VERSION "WUFR 25.1.0"

BS_: 1000000 : 0,0

BU_: FSB DAQ RSB CTRLB

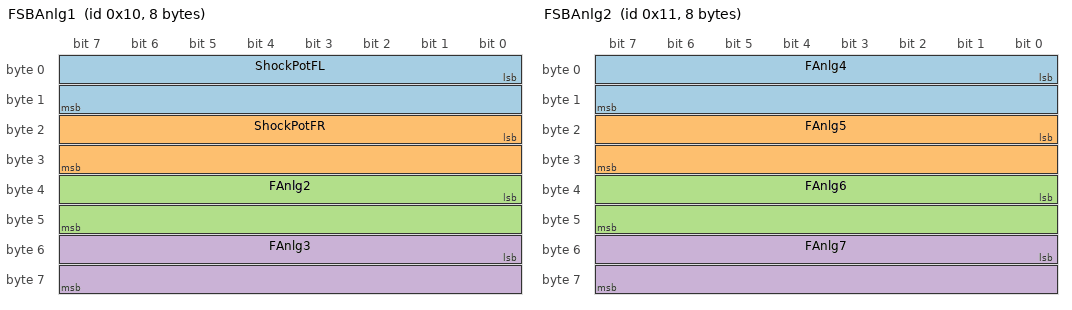
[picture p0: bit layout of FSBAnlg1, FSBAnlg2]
BO_ 16 FSBAnlg1: 8 FSB
 SG_ ShockPotFL : 0|16@1+ (0.013986,-0.0112) [0|50] "mm" DAQ
 SG_ ShockPotFR : 16|16@1+ (0.013986,-0.0112) [0|50] "mm" DAQ
 SG_ FAnlg2 : 32|16@1+ (0.001,0) [0|5] "V" DAQ
 SG_ FAnlg3 : 48|16@1+ (0.001,0) [0|5] "V" DAQ

BO_ 17 FSBAnlg2: 8 FSB
 SG_ FAnlg4 : 0|16@1+ (0.001,0) [0|5] "V" DAQ
 SG_ FAnlg5 : 16|16@1+ (0.001,0) [0|5] "V" DAQ
 SG_ FAnlg6 : 32|16@1+ (0.001,0) [0|5] "V" DAQ
 SG_ FAnlg7 : 48|16@1+ (0.001,0) [0|5] "V" DAQ

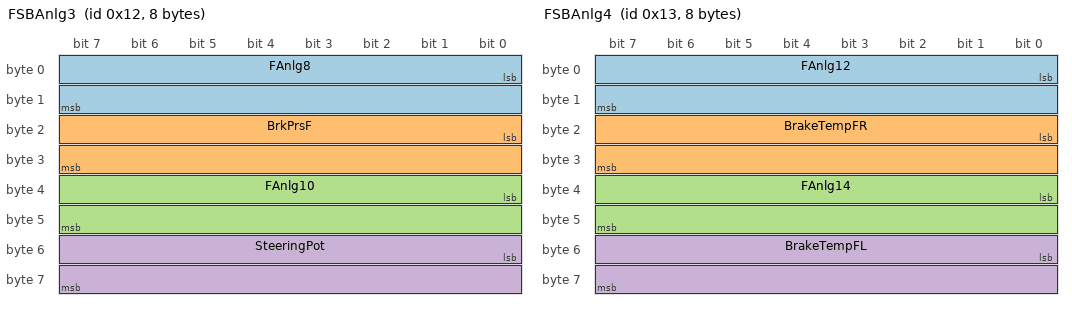
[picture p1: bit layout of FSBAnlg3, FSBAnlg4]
BO_ 18 FSBAnlg3: 8 FSB
 SG_ FAnlg8 : 0|16@1+ (0.001,0) [0|5] "V" DAQ
 SG_ BrkPrsF : 16|16@1+ (0.25,-125.0) [-125|1125] "Psi" DAQ
 SG_ FAnlg10 : 32|16@1+ (0.001,0) [0|5] "V" DAQ
 SG_ SteeringPot : 48|16@1+ (0.83044,-315.013) [-90|90] "deg" DAQ

BO_ 19 FSBAnlg4: 8 FSB
 SG_ FAnlg12 : 0|16@1+ (0.001,0) [0|5] "V" DAQ
 SG_ BrakeTempFR : 16|16@1+ (1.656,-968) [-148|1652] "F" DAQ
 SG_ FAnlg14 : 32|16@1+ (0.001,0) [0|5] "V" DAQ
 SG_ BrakeTempFL : 48|16@1+ (1.656,-968) [-148|1652] "F" DAQ

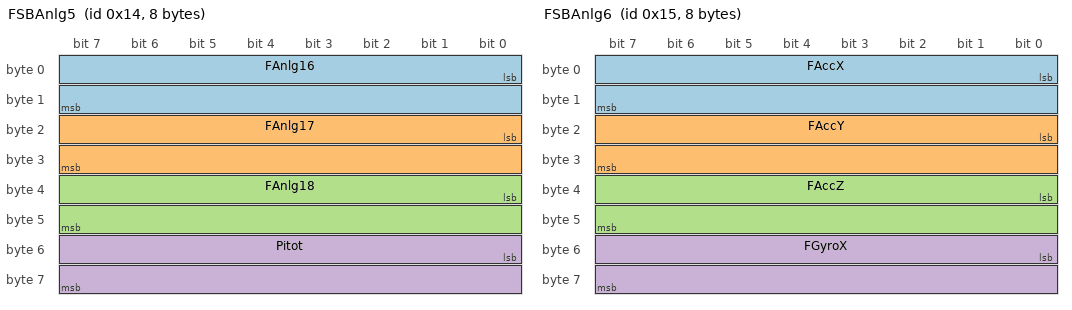
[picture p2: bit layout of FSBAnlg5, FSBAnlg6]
BO_ 20 FSBAnlg5: 8 FSB
 SG_ FAnlg16 : 0|16@1+ (0.001,0) [0|5] "V" DAQ
 SG_ FAnlg17 : 16|16@1+ (0.001,0) [0|5] "V" DAQ
 SG_ FAnlg18 : 32|16@1+ (0.001,0) [0|5] "V" DAQ
 SG_ Pitot : 48|16@1+ (0.00326,-1.63) [0|13.04] "mbar" DAQ

BO_ 21 FSBAnlg6: 8 FSB
 SG_ FAccX : 0|16@1- (0.01,0) [-3276|3276] "m/s^2" DAQ
 SG_ FAccY : 16|16@1- (0.01,0) [-3276|3276] "m/s^2" DAQ
 SG_ FAccZ : 32|16@1- (0.01,0) [-3276|3276] "m/s^2" DAQ
 SG_ FGyroX : 48|16@1- (0.01,0) [-3276|3276] "deg/s^2" DAQ

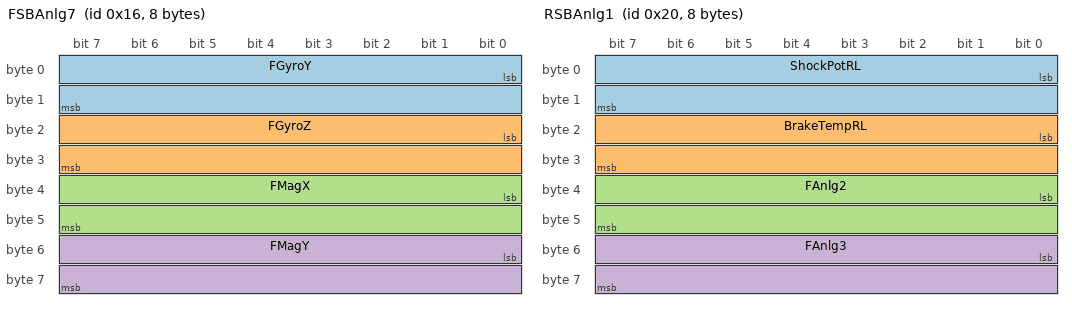
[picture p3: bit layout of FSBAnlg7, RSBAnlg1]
BO_ 22 FSBAnlg7: 8 FSB
 SG_ FGyroY : 0|16@1- (0.01,0) [-3276|3276] "deg/s^2" DAQ
 SG_ FGyroZ : 16|16@1- (0.01,0) [-3276|3276] "deg/s^2" DAQ
 SG_ FMagX : 32|16@1- (0.01,0) [-3276|3276] "#" DAQ
 SG_ FMagY : 48|16@1- (0.01,0) [-3276|3276] "#" DAQ

BO_ 23 FSBAnlg8: 8 FSB
 SG_ FMagZ : 0|16@1+ (0.01,0) [-3276|3276] "#" DAQ
 SG_ RideHeightFR : 16|16@1+ (1,0) [0,255] "mm" DAQ
 SG_ RideHeightFL : 32|16@1+ (1,0) [0,255] "mm" DAQ

BO_ 32 RSBAnlg1: 8 RSB
 SG_ ShockPotRL : 0|16@1+ (0.013986,-0.0112) [0|50] "mm" DAQ
 SG_ BrakeTempRL : 16|16@1+ (1.656,-968) [-148|1652] "F" DAQ
 SG_ FAnlg2 : 32|16@1+ (0.001,0) [0|5] "V" DAQ
 SG_ FAnlg3 : 48|16@1+ (0.001,0) [0|5] "V" DAQ

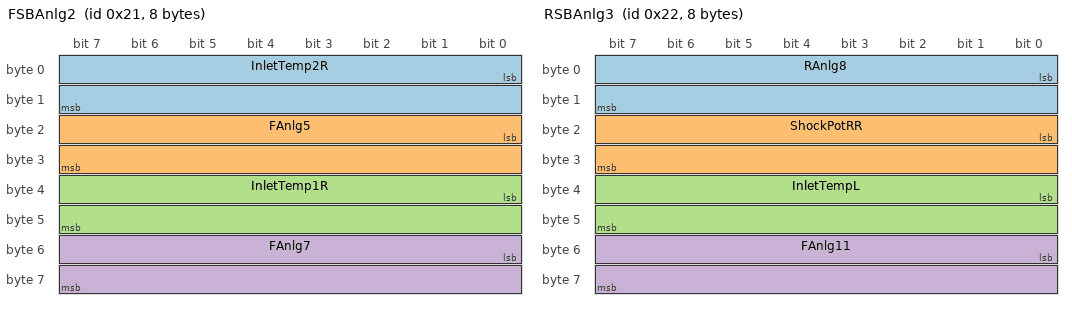
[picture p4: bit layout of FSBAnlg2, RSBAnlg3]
BO_ 33 FSBAnlg2: 8 RSB
 SG_ InletTemp2R : 0|16@1- (-0.13101462,375.7208) [375.7208|-279.3523] "F" DAQ
 SG_ FAnlg5 : 16|16@1+ (0.001,0) [0|5] "V" DAQ
 SG_ InletTemp1R : 32|16@1- (-0.13101462,375.7208) [375.7208|-279.3523] "F" DAQ
 SG_ FAnlg7 : 48|16@1+ (0.001,0) [0|5] "V" DAQ

BO_ 34 RSBAnlg3: 8 RSB
 SG_ RAnlg8 : 0|16@1+ (0.001,0) [0|5] "V" DAQ
 SG_ ShockPotRR : 16|16@1+ (0.013986,-0.0112) [0|50] "mm" DAQ
 SG_ InletTempL : 32|16@1- (-0.13101462,375.7208) [375.7208|-279.3523] "F" DAQ
 SG_ FAnlg11 : 48|16@1+ (0.001,0) [0|5] "V" DAQ

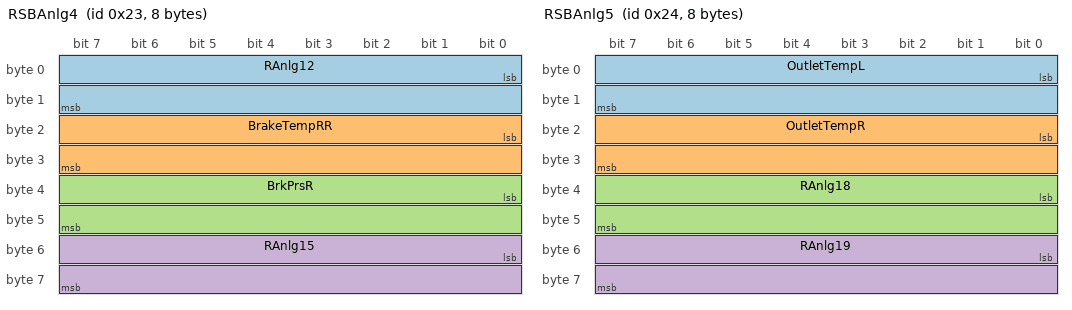
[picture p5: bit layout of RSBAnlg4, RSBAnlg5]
BO_ 35 RSBAnlg4: 8 RSB
 SG_ RAnlg12 : 0|16@1+ (0.001,0) [0|5] "V" DAQ
 SG_ BrakeTempRR : 16|16@1+ (1.656,-968) [-148|1652] "F" DAQ
 SG_ BrkPrsR : 32|16@1+ (0.25,-125.0) [-125|1125] "Psi" DAQ
 SG_ RAnlg15 : 48|16@1+ (0.001,0) [0|5] "V" DAQ

BO_ 36 RSBAnlg5: 8 RSB
 SG_ OutletTempL : 0|16@1- (-0.13101462,375.7208) [375.7208|-279.3523] "F" DAQ
 SG_ OutletTempR : 16|16@1- (-0.13101462,375.7208) [375.7208|-279.3523] "F" DAQ
 SG_ RAnlg18 : 32|16@1+ (0.001,0) [0|5] "V" DAQ
 SG_ RAnlg19 : 48|16@1+ (0.001,0) [0|5] "V" DAQ

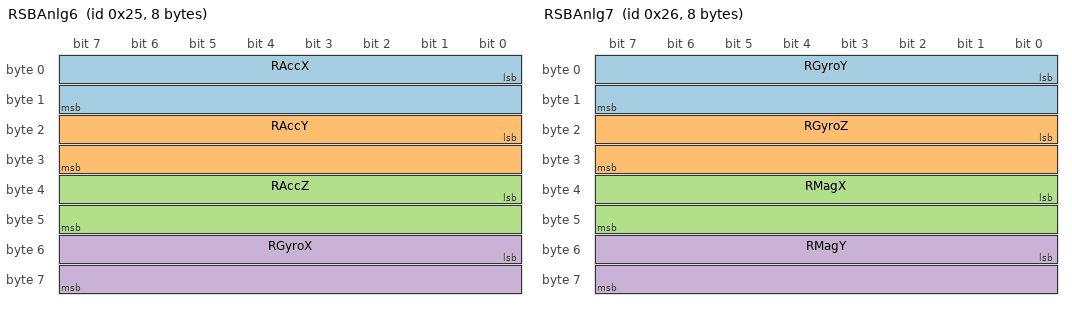
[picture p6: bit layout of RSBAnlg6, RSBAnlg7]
BO_ 37 RSBAnlg6: 8 RSB
 SG_ RAccX : 0|16@1- (0.01,0) [-3276|3276] "m/s^2" DAQ
 SG_ RAccY : 16|16@1- (0.01,0) [-3276|3276] "m/s^2" DAQ
 SG_ RAccZ : 32|16@1- (0.01,0) [-3276|3276] "m/s^2" DAQ
 SG_ RGyroX : 48|16@1- (0.01,0) [-3276|3276] "deg/s^2" DAQ

BO_ 38 RSBAnlg7: 8 RSB
 SG_ RGyroY : 0|16@1- (0.01,0) [-3276|3276] "deg/s^2" DAQ
 SG_ RGyroZ : 16|16@1- (0.01,0) [-3276|3276] "deg/s^2" DAQ
 SG_ RMagX : 32|16@1- (0.01,0) [-3276|3276] "#" DAQ
 SG_ RMagY : 48|16@1- (0.01,0) [-3276|3276] "#" DAQ

BO_ 39 RSBAnlg8: 8 RSB
 SG_ RMagZ : 0|16@1+ (0.01,0) [-3276|3276] "#" DAQ

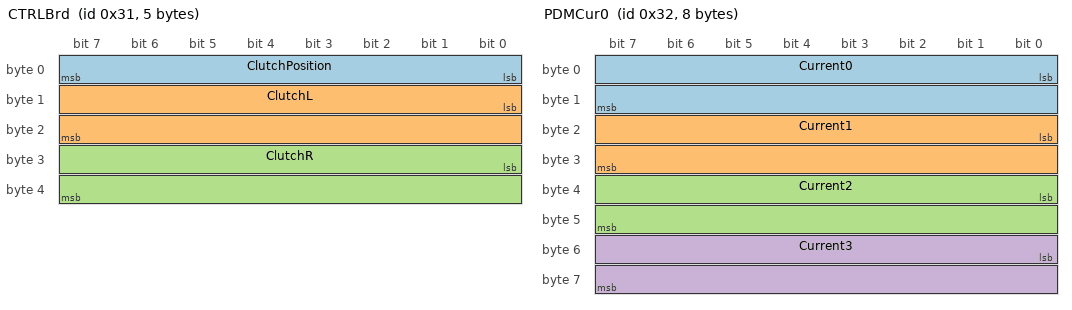
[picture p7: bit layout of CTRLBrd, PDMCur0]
BO_ 49 CTRLBrd: 5 CTRLB
 SG_ ClutchPosition : 0|8@1+ (1,0) [0|255] "Deg" DAQ
 SG_ ClutchL : 8|16@1+ (0.00024414,0) [0|1] "" DAQ
 SG_ ClutchR : 24|16@1+ (0.00024414,0) [0|1] "" DAQ

BO_ 50 PDMCur0: 8 PDM
 SG_ Current0 : 0|16@1- (0.01,0) [0|30] "V" DAQ
 SG_ Current1 : 16|16@1- (0.01,0) [0|30] "V" DAQ
 SG_ Current2 : 32|16@1- (0.01,0) [0|30] "V" DAQ
 SG_ Current3 : 48|16@1- (0.01,0) [0|30] "V" DAQ

CM_ BU_ FSB "Front sensor board";
CM_ BU_ RSB "Rear sensor board";
CM_ BU_ CTRLB "Control board";
BA_DEF_DEF_  "GenMsgCycleTime" 100;
